# ATmega16A register map
Vendor: Atmel; File version: 1.0
CPU: other r0p0, little endian, no MPU, no FPU, 4 interrupt priority bits
Registers are 8-bit, read-write, reset 0x0 unless marked. A register's access mark holds for its fields unless they carry their own. Offsets are from the block's base; [hi:lo] are bit positions; {n}, {i} and the like mark numbered series.

## PORTB — I/O Port
Base 0x00000036
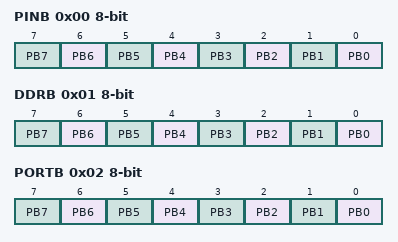
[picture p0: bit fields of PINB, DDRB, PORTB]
0x00 PINB — Port B Input Pins
  [n] PB{n} (n=0..7) — Pin B{n}
0x01 DDRB — Port B Data Direction Register
  [n] PB{n} (n=0..7) — Pin B{n}
0x02 PORTB — Port B Data Register
  [n] PB{n} (n=0..7) — Pin B{n}

## PORTC — I/O Port
Base 0x00000033
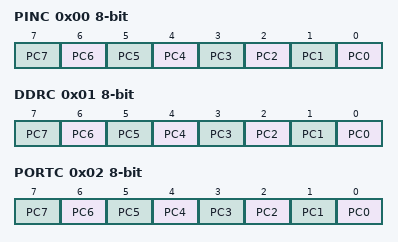
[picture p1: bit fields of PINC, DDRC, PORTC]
0x00 PINC — Port C Input Pins
  [n] PC{n} (n=0..7) — Pin C{n}
0x01 DDRC — Port C Data Direction Register
  [n] PC{n} (n=0..7) — Pin C{n}
0x02 PORTC — Port C Data Register
  [n] PC{n} (n=0..7) — Pin C{n}

## PORTD — I/O Port
Base 0x00000030
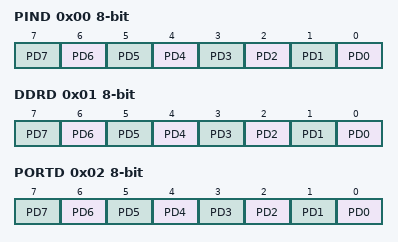
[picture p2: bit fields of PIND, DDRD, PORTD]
0x00 PIND — Port D Input Pins
  [n] PD{n} (n=0..7) — Pin D{n}
0x01 DDRD — Port D Data Direction Register
  [n] PD{n} (n=0..7) — Pin D{n}
0x02 PORTD — Port D Data Register
  [n] PD{n} (n=0..7) — Pin D{n}

## SPI — Serial Peripheral Interface
Base 0x0000002D
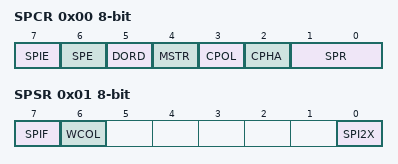
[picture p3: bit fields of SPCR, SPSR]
0x00 SPCR — SPI Control Register
  [7] SPIE — SPI Interrupt Enable
  [6] SPE — SPI Enable
  [5] DORD — Data Order
  [4] MSTR — Master/Slave Select
  [3] CPOL — Clock polarity
  [2] CPHA — Clock Phase
  [1:0] SPR — SPI Clock Rate Selects
    0=fosc/4; 1=fosc/16; 2=fosc/64; 3=fosc/128
0x01 SPSR — SPI Status Register
  [7] SPIF — SPI Interrupt Flag
  [6] WCOL — Write Collision Flag
  [0] SPI2X — Double SPI Speed Bit
0x02 SPDR — SPI Data Register
  [7:0] SPDR — SPI Data bits

## TC0 — Timer/Counter, 8-bit
Base 0x00000050
0x00 SFIOR — Special Function IO Register
  [0] PSR10 — Prescaler Reset Timer/Counter1 and Timer/Counter0
0x02 TCNT0 — Timer/Counter 0 Register
  [7:0] TCNT0 — Timer/Counter 0 bits
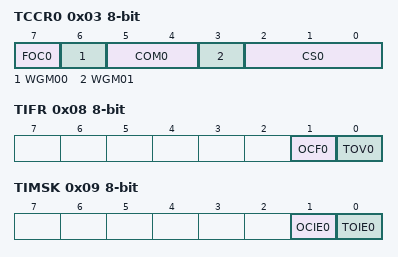
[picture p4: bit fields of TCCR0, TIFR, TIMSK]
0x03 TCCR0 — Timer/Counter Control Register
  [7] FOC0 — Force Output Compare
  [6] WGM00 — Waveform Generation Mode 0
    0=Normal; 1=CTC
  [5:4] COM0 — Compare Match Output Modes
  [3] WGM01 — Waveform Generation Mode 1
  [2:0] CS0 — Clock Selects
    0=No Clock Source (Stopped); 1=Running, No Prescaling; 2=Running, CLK/8; 3=Running, CLK/64; 4=Running, CLK/256; 5=Running, CLK/1024; 6=Running, ExtClk Tx Falling Edge; 7=Running, ExtClk Tx Rising Edge
0x08 TIFR — Timer/Counter Interrupt Flag register
  [1] OCF0 — Output Compare Flag 0
  [0] TOV0 — Timer/Counter0 Overflow Flag
0x09 TIMSK — Timer/Counter Interrupt Mask Register
  [1] OCIE0 — Timer/Counter0 Output Compare Match Interrupt register
  [0] TOIE0 — Timer/Counter0 Overflow Interrupt Enable
0x0C OCR0 — Output Compare 0 Register
  [7:0] OCR0 — Output Compare bits

## TC1 — Timer/Counter, 16-bit
Base 0x00000046
0x00 ICR1 16-bit (reset mask 0xFF) — Timer/Counter1 Input Capture Register Bytes
  [15:0] ICR1 — Timer/Counter1 Input Capture bits
0x02 OCR1B 16-bit (reset mask 0xFF) — Timer/Counter1 Output Compare Register Bytes
  [15:0] OCR1B — Timer/Counter1 Output Compare B bits
0x04 OCR1A 16-bit (reset mask 0xFF) — Timer/Counter1 Output Compare Register Bytes
  [15:0] OCR1A — Timer/Counter1 Output Compare A bits
0x06 TCNT1 16-bit (reset mask 0xFF) — Timer/Counter1 Bytes
  [15:0] TCNT1 — Timer/Counter1 bits
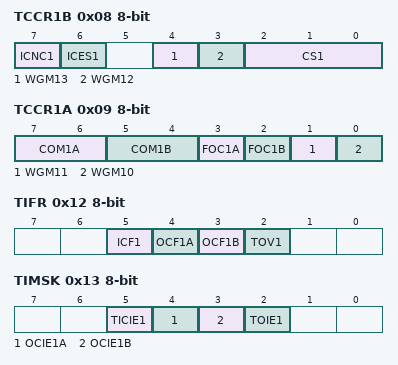
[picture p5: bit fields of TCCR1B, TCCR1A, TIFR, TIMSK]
0x08 TCCR1B — Timer/Counter1 Control Register B
  [7] ICNC1 — Input Capture 1 Noise Canceler
  [6] ICES1 — Input Capture 1 Edge Select
  [4] WGM13 — Waveform Generation Mode
  [3] WGM12 — Waveform Generation Mode
  [2:0] CS1 — Prescaler source of Timer/Counter 1
    0=No Clock Source (Stopped); 1=Running, No Prescaling; 2=Running, CLK/8; 3=Running, CLK/64; 4=Running, CLK/256; 5=Running, CLK/1024; 6=Running, ExtClk Tx Falling Edge; 7=Running, ExtClk Tx Rising Edge
0x09 TCCR1A — Timer/Counter1 Control Register A
  [7:6] COM1A — Compare Output Mode 1A, bits
  [5:4] COM1B — Compare Output Mode 1B, bits
  [3] FOC1A — Force Output Compare 1A
  [2] FOC1B — Force Output Compare 1B
  [1] WGM11 — Waveform Generation Mode
  [0] WGM10 — Waveform Generation Mode
0x12 TIFR — Timer/Counter Interrupt Flag register
  [5] ICF1 — Input Capture Flag 1
  [4] OCF1A — Output Compare Flag 1A
  [3] OCF1B — Output Compare Flag 1B
  [2] TOV1 — Timer/Counter1 Overflow Flag
0x13 TIMSK — Timer/Counter Interrupt Mask Register
  [5] TICIE1 — Timer/Counter1 Input Capture Interrupt Enable
  [4] OCIE1A — Timer/Counter1 Output CompareA Match Interrupt Enable
  [3] OCIE1B — Timer/Counter1 Output CompareB Match Interrupt Enable
  [2] TOIE1 — Timer/Counter1 Overflow Interrupt Enable
